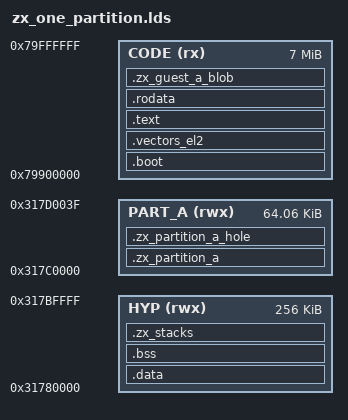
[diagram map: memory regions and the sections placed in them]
/***************************************************************************
 * Copyright (c) 2026 Eclipse ThreadX contributors
 *
 * This program and the accompanying materials are made available under the
 * terms of the MIT License which is available at
 * https://opensource.org/licenses/MIT.
 *
 * AI Disclosure: This file was largely AI-generated by Claude Code (Opus 5).
 * The AI-generated portions may be considered public domain (CC0-1.0)
 * and not subject to the project's licence. The human contributor has
 * reviewed and verified that the code is correct.
 *
 * SPDX-License-Identifier: MIT and CC0-1.0
 **************************************************************************/

/* Link map for the ZoneX one-partition image on the S32Z280-594EVB.
 *
 * WHY THIS IS A SECOND SCRIPT AND NOT AN EXTENSION OF zx_link.lds
 *
 * The two images describe genuinely different memory.  The stage-2 probe has
 * two small partition windows and a relocatable blob copied into both; this
 * one has a single 64 KB window holding a whole ThreadX, and it embeds a
 * guest image that the probe image does not have and must not require.
 *
 * Sharing one script would mean the probe carrying a KEEP for a section it
 * never supplies -- which produces an EMPTY section rather than an error,
 * silently, at whatever address the location counter held.  That is the exact
 * failure the loader's magic-number check exists to catch, and the right
 * place to avoid it is here.
 *
 * THE WINDOW ADDRESS IS A CONTRACT, NOT A CHOICE.  0x317C0000 and 0x10000
 * are written into the guest's own linker script as well, because the guest
 * is LINKED for this window -- every absolute address inside it is baked in.
 * Changing either number means changing both, and the guest declares what it
 * was built for in its own image header so that a mismatch is REFUSED at
 * boot rather than discovered as a fault at a plausible-looking address.
 *
 * A NOTE ON ALIGN, because the two spellings are not equivalent
 *
 * Every ALIGN below is written AFTER the colon, which is the section's
 * ALIGNMENT.  Written before the colon it is the section's ADDRESS,
 * evaluated from a location counter that starts at zero, and it silently
 * overrides the region assignment.  Harmless where memory starts at zero and
 * catastrophic where it does not -- which is what makes it worth repeating
 * in every script here rather than in one of them.
 *
 * ZoneX's OWN code, data, bss and stack are covered by no region at all.
 * That is decision D2: with HSCTLR.BR=1 EL2's own accesses fall back to the
 * background map, while EL0/EL1 accesses that hit no region fault regardless
 * of BR -- so the hypervisor costs no region and is protected from the guest
 * precisely by not being mapped.
 */

ENTRY(_start)

__zx_hyp_stack_size = 0x1000;

/* THE PARTITION WINDOW.  Both numbers are duplicated in
   guest_a/link_partition_a.lds and the pair is checked at boot against the
   guest's own image header.  */

__zx_partition_a_base = 0x317C0000;
__zx_partition_a_size = 0x00010000;

MEMORY
{
    /* THREE regions here where the model needs two, because this board has
       two memories rather than one flat DRAM.
       
         CODE    7 MB at 0x79900000, which is also where the core resets.
                 The hypervisor's text and the embedded guest image live
                 here.
         HYP     the first 256 KB of the 512 KB data SRAM at 0x31780000:
                 the hypervisor's own data, bss and stack.
         PART_A  a 64 KB partition window higher in the same data SRAM,
                 plus one granule of ungranted memory after it.
    
       The partition window is in DATA and not in CODE, and that is forced
       rather than chosen: a partition needs its code and its data in ONE
       CONTIGUOUS window -- one stage-2 region, and a blob that objcopy does
       not pad out to the 1.2 GB between the two memories.  The Cortex-R52
       Modules port work put its module area in data SRAM for the same
       reason.

       Declared as separate regions rather than reached by assignment so that
       the window's address is stated.  A script that arrived at 0x317C0000
       by advancing a location counter would place it correctly today and
       move it silently the first time the hypervisor's own data grew.  */

    CODE   (rx)  : ORIGIN = 0x79900000, LENGTH = 0x00700000    /* 7 MB    */
    HYP    (rwx) : ORIGIN = 0x31780000, LENGTH = 0x00040000    /* 256 KB  */
    PART_A (rwx) : ORIGIN = 0x317C0000, LENGTH = 0x00010040    /* + hole  */
}

SECTIONS
{
    . = ALIGN(64);

    /* .boot MUST come first: MC_ME_PRTN0_CORE0_ADDR is 0x79900000 on this
       board, so whatever lands at the start of CODE is what the core
       executes out of reset, and that has to be _start -- as a T32
       instruction, since the core resets in Thumb state.  The EL2 vector
       table needs alignment but not a fixed address, because HVBAR is
       programmed at run time, so it follows rather than leads.  */

    .boot :
    {
        KEEP(*(.text.boot))
    } > CODE

    .vectors_el2 :
    {
        KEEP(*(.vectors_el2))
    } > CODE

    .text :
    {
        *(.text*)
        *(.glue_7)
        *(.glue_7t)
    } > CODE

    .rodata :
    {
        . = ALIGN(4);
        *(.rodata*)
        . = ALIGN(4);
    } > CODE

    /* ------------------------------------------------------------------
       THE GUEST IMAGE, in the hypervisor's own memory.

       Covered by no stage-2 region, exactly like the rest of ZoneX, so a
       running partition cannot read the image it was loaded from -- which
       matters more than it looks: a partition able to read its own source
       image could also read the NEXT partition's, and the isolation claim
       would be about the copies rather than about the originals.
       ------------------------------------------------------------------ */

    .zx_guest_a_blob : ALIGN(64)
    {
        __zx_guest_a_blob_start = .;
        KEEP(*(.zx_guest_a_blob))
        . = ALIGN(4);
        __zx_guest_a_blob_end = .;
    } > CODE

    .data : ALIGN(64)
    {
        __zx_data_start = .;
        *(.data*)
        . = ALIGN(4);
        __zx_data_end = .;
    } > HYP

    .bss (NOLOAD) : ALIGN(64)
    {
        __zx_bss_start = .;
        *(.bss*)
        *(COMMON)
        . = ALIGN(4);
        __zx_bss_end = .;
    } > HYP

    /* SP must stay 8-byte aligned (AAPCS), so the area is aligned before
       its top symbol is taken.  */

    .zx_stacks (NOLOAD) :
    {
        . = ALIGN(8);
        . = . + __zx_hyp_stack_size;
        __zx_hyp_stack_top = .;
    } > HYP

    . = ALIGN(8);
    _end = .;
    PROVIDE(end = .);

    /* ------------------------------------------------------------------
       PARTITION A'S WINDOW, and the ungranted granule after it.

       NOLOAD: there is nothing in this ELF to load here.  The contents
       arrive at run time, when the loader copies the guest image in, which
       is the path a real guest takes and the reason the manifest's
       image_start and image_end are load-bearing rather than decorative.

       THE HOLE IS ADJACENT BY CONSTRUCTION and the ASSERT keeps it that
       way.  An ungranted address far from every grant proves only that
       unmapped memory faults; the defect class worth catching is a region
       whose limit is out by ONE GRANULE, and only an adjacent hole catches
       it.
       ------------------------------------------------------------------ */

    .zx_partition_a (NOLOAD) : ALIGN(64)
    {
        __zx_partition_a_start = .;
        . = . + __zx_partition_a_size;
        __zx_partition_a_end = .;
    } > PART_A

    .zx_partition_a_hole (NOLOAD) : ALIGN(64)
    {
        __zx_partition_a_hole_start = .;
        . = . + 64;
        __zx_partition_a_hole_end = .;
    } > PART_A

    /* ------------------------------------------------------------------
       Assert the geometry the region programming and the loader depend on,
       so that a layout mistake fails the LINK rather than the run.  A
       region whose base is under-aligned does not fault: its low bits land
       on SH, AP and XN and silently change what it grants, which is the
       single hardest failure in this architecture to see.
       ------------------------------------------------------------------ */

    ASSERT((__zx_partition_a_start & 63) == 0,
           "partition A's window base is not 64-byte aligned")
    ASSERT((__zx_partition_a_end & 63) == 0,
           "partition A's window is not a whole number of granules")
    ASSERT(__zx_partition_a_start == __zx_partition_a_base,
           "partition A's window is not at the address the guest was linked for")
    ASSERT(__zx_partition_a_hole_start == __zx_partition_a_end,
           "the ungranted granule is NOT adjacent to partition A's window")

    ASSERT((__zx_guest_a_blob_start & 63) == 0,
           "the guest image is not 64-byte aligned")

    /* THE BLOB IS NOT EMPTY, and this is the check that catches an .incbin
       whose file was missing or a linker input pattern that matched
       nothing.  Asserted against the END OF THE IMAGE HEADER rather than
       against zero, because a blob too small to carry its own header is
       just as useless as one of no size at all -- and the loader's magic
       check would then be reading past the end of the section, which is
       the out-of-bounds read this assert exists to prevent.

       0x90 is ZX_GUEST_IMAGE_OFF_MAGIC + 4, from
       examples/common/zx_guest_abi.h.  A linker script cannot include a C
       header, so the number is restated here -- and it is restated WRONG
       the moment the header moves, which is exactly what happened when the
       mailbox grew to two granules and pushed the entry branch and the
       header from 0x40 to 0x80.  The bound stayed at 0x50, so a blob of
       0x51 to 0x8F bytes linked cleanly and the magic check read past the
       section into whatever followed it.  */

    ASSERT((__zx_guest_a_blob_end - __zx_guest_a_blob_start) >= 0x90,
           "the embedded guest image is empty or too small to carry its header")

    ASSERT((__zx_guest_a_blob_end - __zx_guest_a_blob_start)
               <= __zx_partition_a_size,
           "the embedded guest image does not fit partition A's window")

    /* And the hypervisor's own data must not have reached the window.  The
       separate MEMORY regions make this impossible rather than merely
       unlikely, so this asserts the thing the reader would otherwise have to
       work out from the region lengths.  */

    ASSERT(_end <= __zx_partition_a_base,
           "the hypervisor's own data has grown into partition A's window")

    /* And the window stays out of the half-speed memory.  Nothing would fail
       if it did not; every timing number a later step produced would simply
       be wrong by a factor nobody would think to look for.  */

    ASSERT((__zx_partition_a_base + __zx_partition_a_size) <= 0x31800000,
           "the partition window reaches into DRAM2, which runs at half core speed")
}
